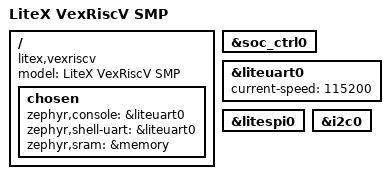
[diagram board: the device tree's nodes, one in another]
/dts-v1/;

#include <riscv32-litex-vexriscv-smp.dtsi>

/ {
	model = "LiteX VexRiscV SMP";
	compatible = "litex,vexriscv";
	chosen {
		zephyr,console = &liteuart0;
		zephyr,shell-uart = &liteuart0;
		zephyr,sram = &memory;
    };
};

&soc_ctrl0 {
	status = "okay";
};

&liteuart0 {
	current-speed = <115200>;
	status = "okay";
};

// &timer0 {
// 	status = "okay";
// };

// &mdio0 {
//     status = "okay";
// };
// 
// // &phy0 {
// //     status = "okay";
// // };
// 
// &eth0 {
//     status = "okay";
// };

&litespi0 {
    status = "okay";
};

&i2c0 {
	status = "okay";
};
